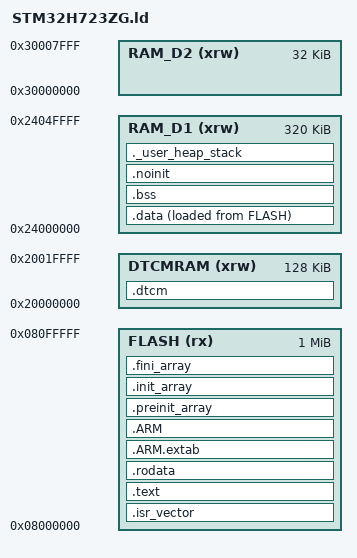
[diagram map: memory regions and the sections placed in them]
/* STM32H723ZG: 1 MB flash, DTCM 128 KB (CPU-only buffers from the bottom, stack from the top), AXI SRAM 320 KB (data, bss, DMA buffers) */
ENTRY(Reset_Handler)
_estack = ORIGIN(DTCMRAM) + LENGTH(DTCMRAM);
_Min_Heap_Size = 0x0;
_Min_Stack_Size = 0x2000;
MEMORY
{
  FLASH   (rx)  : ORIGIN = 0x08000000, LENGTH = 1024K
  DTCMRAM (xrw) : ORIGIN = 0x20000000, LENGTH = 128K
  RAM_D1  (xrw) : ORIGIN = 0x24000000, LENGTH = 320K
  RAM_D2  (xrw) : ORIGIN = 0x30000000, LENGTH = 32K
}
SECTIONS
{
  .isr_vector : { . = ALIGN(4); KEEP(*(.isr_vector)) . = ALIGN(4); } >FLASH
  .text : { . = ALIGN(4); *(.text) *(.text*) *(.glue_7) *(.glue_7t) *(.eh_frame)
            KEEP (*(.init)) KEEP (*(.fini)) . = ALIGN(4); _etext = .; } >FLASH
  .rodata : { . = ALIGN(4); *(.rodata) *(.rodata*) . = ALIGN(4); } >FLASH
  .ARM.extab : { *(.ARM.extab* .gnu.linkonce.armextab.*) } >FLASH
  .ARM : { __exidx_start = .; *(.ARM.exidx*) __exidx_end = .; } >FLASH
  .preinit_array : { PROVIDE_HIDDEN (__preinit_array_start = .); KEEP (*(.preinit_array*)) PROVIDE_HIDDEN (__preinit_array_end = .); } >FLASH
  .init_array : { PROVIDE_HIDDEN (__init_array_start = .); KEEP (*(SORT(.init_array.*))) KEEP (*(.init_array*)) PROVIDE_HIDDEN (__init_array_end = .); } >FLASH
  .fini_array : { PROVIDE_HIDDEN (__fini_array_start = .); KEEP (*(SORT(.fini_array.*))) KEEP (*(.fini_array*)) PROVIDE_HIDDEN (__fini_array_end = .); } >FLASH
  _sidata = LOADADDR(.data);
  .data : { . = ALIGN(4); _sdata = .; *(.data) *(.data*) . = ALIGN(4); _edata = .; } >RAM_D1 AT> FLASH
  .bss : { . = ALIGN(4); _sbss = .; __bss_start__ = _sbss; *(.bss) *(.bss*) *(COMMON) . = ALIGN(4); _ebss = .; __bss_end__ = _ebss; } >RAM_D1
  /* kept over a reset (not zeroed): the fault record */
  .noinit (NOLOAD) : { . = ALIGN(4); *(.noinit) *(.noinit*) . = ALIGN(4); } >RAM_D1
  /* CPU-only buffers (not reachable by DMA1/2): the spectrum diagnostic (common/spec.c); not zeroed at boot */
  .dtcm (NOLOAD) : { . = ALIGN(8); _sdtcm = .; *(.dtcm) *(.dtcm*) . = ALIGN(8); _edtcm = .; } >DTCMRAM
  ASSERT(_estack - _edtcm >= 32K, "DTCM: less than 32 KB left for the stack")
  ._user_heap_stack : { . = ALIGN(8); PROVIDE ( end = . ); PROVIDE ( _end = . ); . = . + _Min_Heap_Size; . = ALIGN(8); } >RAM_D1
  /DISCARD/ : { libc.a ( * ) libm.a ( * ) libgcc.a ( * ) }
  .ARM.attributes 0 : { *(.ARM.attributes) }
}
